# Polarfire SoC register map
Vendor: Microchip; File version: 1.0
CPU: Microchip PolarFire SoC 1.0, little endian
Registers are 32-bit, read-write, reset 0x0 unless marked. A register's access mark holds for its fields unless they carry their own. Offsets are from the block's base; [hi:lo] are bit positions; lines under a group give offsets from that group; {n}, {i} and the like mark numbered series.

## EMMC_SD (part 2 of 2) — EMMC_SD Controller
Base 0x20008000
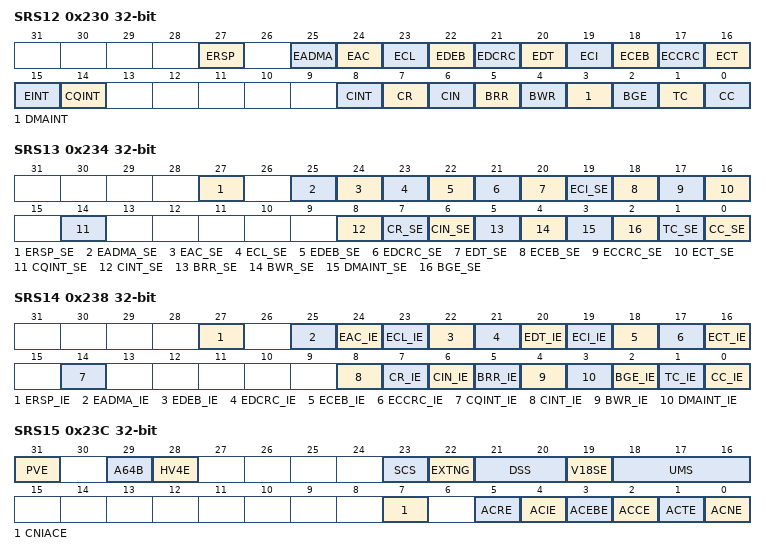
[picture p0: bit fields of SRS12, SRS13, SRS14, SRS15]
0x230 SRS12 — SRS12 - Error/Normal Interrupt Status
  [27] ERSP — ERSP - Response Error (SD Mode only) Generated on error detection inside R1 or R5 response. Errors will be checked only if RECE is set 1.
  [25] EADMA — EADMA - ADMA Error Generated when an error occurs during ADMA read or write transfer. To resolve the cause of the error, the state of the ADMA engine at error occurrence is saved in ADMA Error Status register, and the address of the descriptor processed at error occurrence is provided in ADMA System Address register.
  [24] EAC — EAC - Auto CMD Error (SD mode only) Generated when an error occurs during Auto CMD12/Auto CMD23 command transmission. It indicates one of the following conditions: - one of the bits in SRS15 register has changed from 0 to 1, - Auto CMD12 is not executed due to the previous command error.
  [23] ECL — ECL - Current Limit Error Generated when host is not supplying power to SD card due to some failure. The value is equal to the actual signal level on cle pin of the host.
  [22] EDEB — EDEB - Data End Bit Error (SD mode only) When set to 1, indicates detecting 0 at the end bit position of read data transfer which uses the DAT line, or at the end bit position of the Write CRC Status.
  [21] EDCRC — EDCRC - Data CRC Error (SD mode only) When set to 1, indicates detecting CRC error when transferring read data which uses the DAT line, or when detecting the Write CRC status having a value of other than 010. This bit will be set to 1 immediately when conflict on CMD line detected. The conflict is signalized by setting this bit and SRS12.EDT to 1.
  [20] EDT — EDT - Data Timeout Error (SD mode only) When set to 1, indicates detecting one of the following timeout conditions: 1. Busy timeout for the response with busy. 2. Busy timeout after Write CRC status. 3. Write CRC Status timeout. 4. Read data timeout. This bit will be set to 1 immediately when conflict on CMD line conflict detected.
  [19] ECI — ECI - Command Index Error (SD mode only) When set to 1, indicates that Index error occurs in the command response.
  [18] ECEB — ECEB - Command End Bit Error (SD mode only) When set to 1, indicates detecting that the end bit of a command response is 0.
  [17] ECCRC — ECCRC - Command CRC Error (SD mode only) When set to 1, indicates that command CRC error has occurred.
  [16] ECT — ECT - Command Timeout Error (SD mode only) When set to 1, indicates that no response was returned within 64 SDCLK cycles from the end bit of the command.
  [15] EINT ro — EINT - Error Interrupt This bit is set if: - any of bits in range SRS12[31:16] is set; The software can check for an error by reading this single bit first.
  [14] CQINT ro — CQINT - Command Queuing Interrupt This interrupt is asserted when at least one of the bits in CQIS register is set. This interrupt is cleared only by clearing the source interrupt in CQIS register.
  [8] CINT ro — CINT - Card Interrupt Indicates the card interrupt. CINT is not sampled by the card clock, so the interrupt can be detected even with SD clock stopped (SRS11.SDCE=0). Also, CINT is not cleared by writing 1. Instead, the software will clear the source of an interrupt inside the card.After detecting the Card Interrupt, the software will stop further interrupt detection by clearing SRS13.CINT_SE to 0. Then, the software will clear the interrupt source inside the card by using the appropriate commands. For the details, please refer to the SDIO Card Specification. After clearing the interrupt source, the card will stop to drive the interrupt signal to the host. Finally, when the interrupt service routine is finished, the interrupt detection can be enabled by setting SRS13.CINT_SE back to 1.
  [7] CR — CR - Card Removal Generated when the SRS09.CI bit changes from 1 to 0, indicating card removal event. When read as 1, indicates that the card was removed from the slot. When read as 0, indicates that the card state is stable (still inserted or removed) or that the debouncing is in progress.
  [6] CIN — CIN - Card Insertion Generated when the SRS09.CI bit changes from 0 to 1, indicating card insertion. When read as 1, indicates that the card was inserted to the slot. When read as 0, indicates that the card state is stable (still inserted or removed) or that the debouncing is in progress.
  [5] BRR — BRR - Buffer Read Ready Generated when the BRE changes from 0 to 1, indicating that the data buffer can be read by the software.
  [4] BWR — BWR - Buffer Write Ready Generated when the BWE changes from 0 to 1, indicating that the data buffer can be written by the software.
  [3] DMAINT — DMAINT - DMA Interrupt In SDMA mode, DMA interrupt is generated when the host controller detects the Host SDMA Buffer boundary. In ADMA mode, DMA interrupt is generated when the INT flag is set in a currently serviced ADMA descriptor.
  [2] BGE — BGE - Block Gap Event Generated when the read/write transaction is stopped at a block gap as the result of setting SRS10.SBGR to 1.
  [1] TC — TC - Transfer Complete SD Mode: Generated when the transfer which uses the DAT line is complete. Transfers which use the DAT line include the read/write transfers and commands with a busy response. In case of the read transfer, TC indicates that the entire data was transferred from the card to the host system (i.e. the host FIFO is empty after reading the last data block). In case of the write transfer, TC indicates that the entire data was transferred from the host to the card (i.e. the host FIFO is empty after writing the last data block), and the card accepted the data (busy signal released after the last block). In the case of the command with a busy response, TC indicates that the busy signal is released after the response.
  [0] CC — CC - Command Complete Generated when the end bit of the response is received, except the response for Auto-CMD12 command. Auto-CMD12 command does not generate CC.
0x234 SRS13 — SRS13 - Error/Normal Status Enable
  [27] ERSP_SE — ERSP_SE - Response Error Status Enable (SD mode only) 1 - enabled 0 - masked
  [25] EADMA_SE — EADMA_SE - ADMA Error Status Enable (SD mode only) 1 - enabled 0 - masked
  [24] EAC_SE — EAC_SE - Auto CMD Error Status Enable (SD mode only) 1 - enabled 0 - masked
  [23] ECL_SE — ECL_SE - Current Limit Error Status Enable (SD mode only) 1 - enabled 0 - masked
  [22] EDEB_SE — EDEB_SE - Data End Bit Error Status Enable (SD mode only) 1 - enabled 0 - masked
  [21] EDCRC_SE — EDCRC_SE - Data CRC Error Status Enable (SD mode only) 1 - enabled 0 - masked
  [20] EDT_SE — EDT_SE - Data Timeout Error Status Enable (SD mode only) 1 - enabled 0 - masked
  [19] ECI_SE — ECI_SE - Command Index Error Status Enable (SD mode only) 1 - enabled 0 - masked
  [18] ECEB_SE — ECEB_SE - Command End Bit Error Status Enable (SD mode only) 1 - enabled 0 - masked
  [17] ECCRC_SE — ECCRC_SE - Command CRC Error Status Enable (SD mode only) 1 - enabled 0 - masked
  [16] ECT_SE — ECT_SE - Command Timeout Error Status Enable (SD mode only) 1 - enabled 0 - masked
  [14] CQINT_SE — CQINT_SE - Command Queuing Status Enable 1 - enabled 0 - masked
  [8] CINT_SE — CINT_SE - Card Interrupt Status Enable 1 - enabled 0 - masked
  [7] CR_SE — CR_SE - Card Removal Status Enable 1 - enabled 0 - masked
  [6] CIN_SE — CIN_SE -Card Insertion Status Enable 1 - enabled 0 - masked
  [5] BRR_SE — BRR_SE - Buffer Read Ready Status Enable 1 - enabled 0 - masked
  [4] BWR_SE — BWR_SE - Buffer Write Ready Status Enable 1 - enabled 0 - masked
  [3] DMAINT_SE — DMAINT_SE - DMA Interrupt Status Enable 1 - enabled 0 - masked
  [2] BGE_SE — BGE_SE - Block Gap Event Status Enable 1 - enabled 0 - masked
  [1] TC_SE — TC_SE - Transfer Complete Status Enable 1 - enabled 0 - masked
  [0] CC_SE — CC_SE - Command Complete Status Enable 1 - enabled 0 - masked
0x238 SRS14 — SRS14 - Error/Normal Signal Enable
  [27] ERSP_IE — ERSP_IE - Response Error Interrupt Enable 1 - enabled 0 - masked
  [25] EADMA_IE — EADMA_IE - ADMA Error Interrupt Enable (SD mode only) 1 - enabled 0 - masked
  [24] EAC_IE — EAC_IE - Auto CMD Error Interrupt Enable (SD mode only) 1 - enabled 0 - masked
  [23] ECL_IE — ECL_IE - Current Limit Error Interrupt Enable (SD mode only) 1 - enabled 0 - masked
  [22] EDEB_IE — EDEB_IE - Data End Bit Error Interrupt Enable (SD mode only) 1 - enabled 0 - masked
  [21] EDCRC_IE — EDCRC_IE - Data CRC Error Interrupt Enable (SD mode only) 1 - enabled 0 - masked
  [20] EDT_IE — EDT_IE - ata Timeout Error Interrupt Enable (SD mode only) 1 - enabled 0 - masked
  [19] ECI_IE — ECI_IE - Command Index Error Interrupt Enable (SD mode only) 1 - enabled 0 - masked
  [18] ECEB_IE — ECEB_IE - Command End Bit Error Interrupt Enable (SD mode only) 1 - enabled 0 - masked
  [17] ECCRC_IE — ECCRC_IE - Command CRC Error Interrupt Enable (SD mode only) 1 - enabled 0 - masked
  [16] ECT_IE — ECT_IE - Command Timeout Error Interrupt Enable (SD mode only) 1 - enabled 0 - masked
  [14] CQINT_IE — CQINT_IE - Command Queuing - Interrupt Enable 1 - enabled 0 - masked
  [8] CINT_IE — CINT_IE - Card Interrupt - Interrupt Enable 1 - enabled 0 - masked
  [7] CR_IE — CR_IE - Card Removal Interrupt Enable 1 - enabled 0 - masked
  [6] CIN_IE — CIN_IE - Card Insertion Interrupt Enable 1 - enabled 0 - masked
  [5] BRR_IE — BRR_IE - Buffer Read Ready Interrupt Enable 1 - enabled 0 - masked
  [4] BWR_IE — BWR_IE - Buffer Write Ready Interrupt Enable 1 - enabled 0 - masked
  [3] DMAINT_IE — DMAINT_IE - DMA Interrupt Enable 1 - enabled 0 - masked
  [2] BGE_IE — BGE_IE - Block Gap Event Interrupt Enable 1 - enabled 0 - masked
  [1] TC_IE — TC_IE - Transfer Complete Interrupt Enable 1 - enabled 0 - masked
  [0] CC_IE — CC_IE - Command Complete Interrupt Enable 1 - enabled 0 - masked
0x23C SRS15 — SRS15 - Host Control #2 / Auto CMD Error Status
  [31] PVE — PVE - Preset Value Enable Setting this bit to 1 triggers an automatically update of SRS11.SDCFSL, SRS11.SDCFSH, SRS11.CGS, SRS15.DSS registers by the host. Values for an update are taken from SRS24 - SRS27 and depends on SRS15.UMS.
  [29] A64B — A64B - 64-bit Addressing Specifies the addressing mode for DMA ending. This field is ignored when SRS15.HV4E=0. 0 - 32-bit addressing 1 - 64-bit addressing
  [28] HV4E — HV4E - Host Version 4.00 Enable Selects backward (SD Host 3.00 Version) compatibility mode or SD Host 4.00 Version mode. 0 - Version 3.00 1 - Version 4.00 The software can select system address register SRS00 (when this bit is 0) or SRS23 / SRS22 (when this bit is 1) for the SDMA engine.
  [23] SCS — SCS - Sampling Clock Select (UHS-I only) The host updates this bit when the tuning procedure is finished. If this bit is set to 1, this means that the tuning procedure is successfully completed. Otherwise it means that procedure failed and clock tuning logic is disabled. This bit is valid only after the procedure is finished.Writing 1 will be ignored. Writing 0 will reset and disable tuning block.
  [22] EXTNG — EXTNG - Execute Tuning (UHS-I only) This register controls tuning procedure. The procedure starts when the bit is set 1. The procedure can be aborted when the bit is cleared. The bit is read 1 while the procedure is in progress, and 0 when the procedure is finished. SCS = 0, EXTNG = 0 - Reset and disable clock tuning logic SCS = 0, EXTNG = 1 - Reset and restart tuning process SCS = 1, EXTNG = 0 - Stop tuning procedure SCS = 1, EXTNG = 1 - Start retuning (without clock tuning logic reset)
  [21:20] DSS — DSS - Driver Strength Select (UHS-I only) This bit controls the electric parameters of I/O driver. Up to 4 configurations of I/O driver settings can be implemented: 00 - Driver Type B (default) 01 - Driver Type A 10 - Driver Type C 11 - Driver Type D The bit is ignored when the V18SE is cleared.
  [19] V18SE — V18SE - 1.8V Signaling Enable (UHS-I only) This bit controls I/O signaling voltage level. If the bit is 0 or 1, the I/O uses the 3.3V or 1.8V signaling, respectively. The SW driver will set this bit 1 when UHS-I mode. Depend on the selected SD interface mode, the software will set this field as follows: - 0 - for Default Speed, High Speed mode - 1 - for UHS-I mode
  [18:16] UMS — UMS - UHS Mode Select Used to select one of UHS-I modes . 000b - SDR12 001b - SDR25 010b - SDR50 011b - SDR104 100b - DDR50 101b - Reserved 110b - Reserved 111b - Reserved The selected UHS-I mode (when value is in range 000b-100b) will be ignored when V18SE is 0.
    0=SDR12; 1=SDR25; 2=SDR50; 3=SDR104; 4=DDR50; 6=Reserverd2
  [7] CNIACE ro — CNIACE - Command Not Issued By Auto CMD12 Error When read as 1, the command was not executed by the Host due to the previous Auto CMD12 error. When Host detects any error during Auto-CMD12, then all further command generation attempts are blocked. The software reset sequence is needed for recovery. Bit is set to 0, when Auto CMD23 Error is detected (any of bits SRS15[4:1] is set).
  [5] ACRE ro — ACRE - Auto CMD Response Error When read as 1, means an error is detected in response to Auto Command.
  [4] ACIE ro — ACIE - Auto CMD Index Error When read as 1, means that Command Index error occurred in the Auto CMD response.
  [3] ACEBE ro — ACEBE - Auto CMD End Bit Error When read as 1, indicates that the end bit of the Auto-CMD response is 0.
  [2] ACCE ro — ACCE - Auto CMD CRC Error When read as 1, indicates a CRC error was detected in the Auto CMD response or conflict on the CMD lines is detected: ACCE(SRS15.2) = 0, ACTE(SRS15.1) = 0 - No error ACCE(SRS15.2) = 0, ACTE(SRS15.1) = 1 - Auto CMD Timeout error detected ACCE(SRS15.2) = 1, ACTE(SRS15.1) = 0 - Auto CMD CRC error detected ACCE(SRS15.2) = 1, ACTE(SRS15.1) = 1 - Conflict on the CMD line detected
  [1] ACTE ro — ACTE - Auto CMD Timeout Error When read as 1, indicates that there was no response within 64 SDCLK clock cycles from the end bit of the Auto CMD or conflict on the CMD lines is detected (see table in SRS15.ACCE field description). If this bit is set to 1, the other error status bits (SRS15[4:2]) are meaningless.
  [0] ACNE ro — ACNE - Auto CMD12 Not Executed When set to 1, means the host cannot issue Auto CMD12 due to some error. If this bit is set to 1, other error status bits (SRS15[4:1]) are meaningless. Bit is updated with 0, when Auto CMD23 Error is detected (any of bits SRS15[4:1] is set).
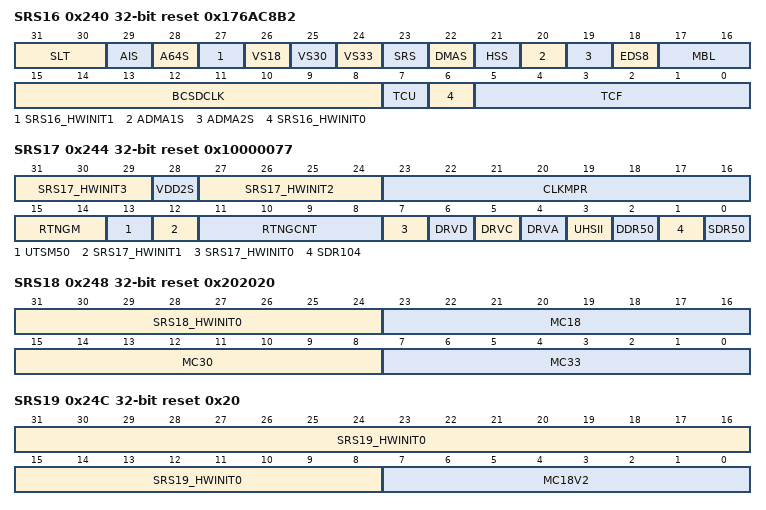
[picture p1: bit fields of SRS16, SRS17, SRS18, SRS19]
0x240 SRS16 ro reset 0x176AC8B2 — SRS16 - Capabilities #1 HWINIT Register - Note this register is hardware initialized after reset and the value read back will match the IP configuration.
  [31:30] SLT — SLT - Slot Type These bits inform what type of slot is provided. 00 - Removable Card Slot 01 - Embedded Slot for One Device 10 - Shared Bus Slot 11 - Reserved
  [29] AIS — AIS - Asynchronous Interrupt Support 0 - not supported 1 - supported
  [28] A64S — A64S - 64-bit System Addressing Support 0 - not supported 1 - supported
  [27] SRS16_HWINIT1 — HWINIT field
  [26] VS18 — VS18 - Voltage Support 1.8V 0 - not supported 1 - supported
  [25] VS30 — VS30 - Voltage Support 3.0V 0 - not supported 1 - supported
  [24] VS33 — VS33 - Voltage Support 3.3V 0 - not supported 1 - supported
  [23] SRS — SRS - Suspend / Resume Support 0 - not supported 1 - supported The host controller does not support Suspend / Resume mechanism.
  [22] DMAS — DMAS - SDMA Support 0 - not supported 1 - supported This bit defines whether the SDMA is supported in the slot. There is a separate IMPLEMENT_DMA generic parameter which defines whether the DMA is physically implemented inside host. If DMAS is set to 1 for any card slot, then the IMPLEMENT_DMA would also be set to 1.
  [21] HSS — HSS - High Speed Support 0 - not supported 1 - supported
  [20] ADMA1S — ADMA1S - ADMA1 Support 0 - not supported 1 - supported
  [19] ADMA2S — ADMA2S - ADMA2 Support 0 - not supported 1 - supported
  [18] EDS8 — 8EDS - 8-bit Embedded Device Support 0 - not supported 1 - supported If this bit is 0, the SRS10.EDTW register is not implemented.
  [17:16] MBL — SRS16.MBL - Max Block Length This value indicates the maximum block size that can be transferred by the host. Three sizes can be defined as indicated below: 00b - 512 Bytes 01b - 1024 Bytes 10b - 2048 Bytes 11b - Reserved The physical FIFO buffer size is defined by the separate FIFODEPTH generic parameter, and the physical buffer size is equal to 2^FIFODEPTH * 8 bytes. Therefore, the Maximum Block Size defined by MBL will always be less or equal to the physical buffer size.
  [15:8] BCSDCLK — BCSDCLK - Base Clock Frequency for SD Clock Field defines the base clock frequency for the SD Clock in 1MHz units. The base clock is the clock sourced to sdmclk pin of the host. The maximum clock frequency supported is between 10MHz to 255MHz. If BCSDCLK = 0, the Host System has to obtain the clock information via another method (i.e. not defined by the specification).
  [7] TCU — TCU - Timeout Clock Unit Field defines the frequency unit for the SRS16.TCF. 0 - kHz 1 - MHz
  [6] SRS16_HWINIT0 — HWINIT field
  [5:0] TCF — TCF - Timeout Clock Frequency Defines the base clock frequency used to detect Data Timeout Error. The SRS16.TCU bit determines the unit used. 111111b - 63kHz(SRS16.TCU=0) or 63MHz(SRS16.TCU=1) 111110b - 63kHz(SRS16.TCU=0) or 63MHz(SRS16.TCU=1) ... 000001b - 1kHz(SRS16.TCU=0) or 1MHz(SRS16.TCU=1) 000000b - Host System has to obtain the clock information via another method (i.e. not defined by the spec).
0x244 SRS17 ro reset 0x10000077 — SRS17 - Capabilities #2HWINIT Register - Note this register is hardware initialized after reset and the value read back will match the IP configuration.
  [31:29] SRS17_HWINIT3 — HWINIT field
  [28] VDD2S — VDD2S - VDD2 Supported Information about support or lack of support of optional VDD2.
  [27:24] SRS17_HWINIT2 — HWINIT field
  [23:16] CLKMPR — CLKMPR - Clock Multiplier This field is to be 0 (fixed), as the Clock Multiplier is not supported.
  [15:14] RTNGM — RTNGM - Re-Tuning Modes Depending on the retuning method, the some restrictions are assumed for the data length between re-tunings. The core can work with supporting one of the three method: 0 - Mode1: The software driver will use timer to calculate when the re-tuning is to be rerun. The data length between operations is limited to the 4MB. 1 - Mode2: The driver will use either the re-tuning request (external input pin uhsi_retune_req is used for this purpose) or timer to predict when next retuning should be performed. The data length between operations is limited to the 4MB. 2 - Mode3: This mode is similar to the mode2 with one exception. The core is able to perform auto retuning during the transmission, so data length limitation is not exists. Mode 3 is currently not supported.The driver can configure the timer by getting the RTNGCNT.This field is to be 0 or 1, because the mode 3 is not supported.
  [13] UTSM50 — UTSM50 - Use Tuning for SDR50 1 - tuning operation is necessary in SDR50 mode 0 - tuning operation is not necessary in SDR50 mode
  [12] SRS17_HWINIT1 — HWINIT field
  [11:8] RTNGCNT — RTNGCNT - Timer Count for Re-Tuning These bits contain initial value for timer used to starting periodically Re-Tuning Operation. 0h - Re-Tuning Timer disabled 1h - 1 second ... n - 2^(n-1) seconds ... Bh - 1024 seconds Eh-Ch - Reserved Fh - Obtain this info in other way
  [7] SRS17_HWINIT0 — HWINIT field
  [6] DRVD — DRVD - 1.8V Line Driver Type D Supported 1 - Driver Type D supported 0 - Driver Type D not supported
  [5] DRVC — DRVC - 1.8V Line Driver Type C Supported 1 - Driver Type C supported 0 - Driver Type C not supported
  [4] DRVA — DRVA - 1.8V Line Driver Type A Supported 1 - Driver Type A supported 0 - Driver Type A not supported
  [3] UHSII — UHSII - UHS-II Supported 1 - UHS-II supported 0 - UHS-II not supported
  [2] DDR50 — DDR50 - DDR50 Supported 1 - DDR50 mode supported 0 - DDR50 mode not supported
  [1] SDR104 — SDR104 - SDR104 Supported 1 - SDR104 mode supported 0 - SDR104 mode not supported
  [0] SDR50 — SDR50 - SDR50 Supported 1 - SDR50 mode supported 0 - SDR50 mode not supported
0x248 SRS18 ro reset 0x202020 — SRS18 - Capabilities #3HWINIT Register - Note this register is hardware initialized after reset and the value read back will match the IP configuration.
  [31:24] SRS18_HWINIT0 — HWINIT field
  [23:16] MC18 — MC18 - Maximum Current for 1.8V 0 - Host System has to obtain the current value via another method 1 - 4 mA 2 - 8 mA 3 - 12 mA ... 255 - 1020 mA
  [15:8] MC30 — MC30 - Maximum Current for 3.0V 0 - Host System has to obtain the current value via another method 1 - 4 mA 2 - 8 mA 3 - 12 mA ... 255 - 1020 mA
  [7:0] MC33 — MC33 - Maximum Current for 3.3V 0 - Host System has to obtain the current value via another method 1 - 4 mA 2 - 8 mA 3 - 12 mA ... 255 - 1020 mA
0x24C SRS19 ro reset 0x20 — SRS19 - Capabilities #4 HWINIT Register - Note this register is hardware initialized after reset and the value read back will match the IP configuration.
  [31:8] SRS19_HWINIT0 — HWINIT field
  [7:0] MC18V2 — MC18V2 - Maximum Current for 1.8V VDD2 0 - Host System has to obtain the current value via another method 1 - 4 mA 2 - 8 mA 3 - 12 mA ... 255 - 1020 mA
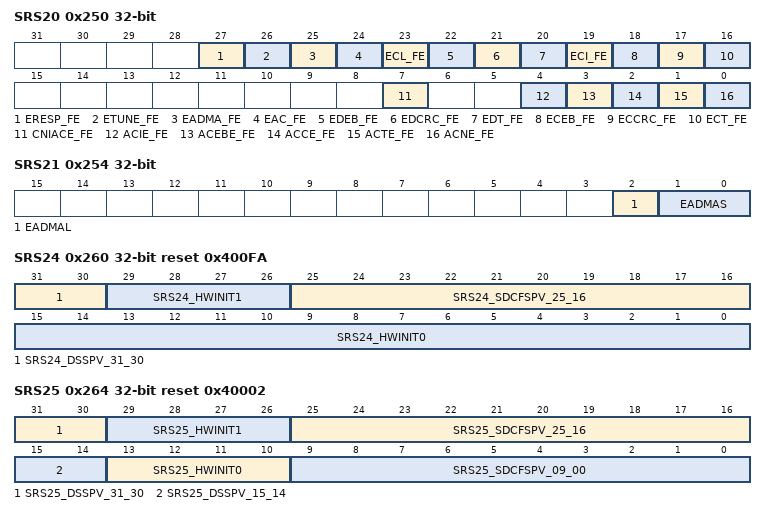
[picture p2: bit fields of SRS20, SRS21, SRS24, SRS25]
0x250 SRS20 — SRS20 - Force Event Each field of this register is related to the specific error status. Writing 1 to field will set the status error. This function is provided for SW debug purpose.
  [27] ERESP_FE — ERESP_FE - Force Response Error Event
  [26] ETUNE_FE — ETUNE_FE - Force Tuning Error Event
  [25] EADMA_FE — EADMA_FE - Force ADMA Error Event
  [24] EAC_FE — EAC_FE - Force Auto CMD Error Event
  [23] ECL_FE — ECL_FE - Force Current Limit Error Event
  [22] EDEB_FE — EDEB_FE - Force Data End Bit Error Event
  [21] EDCRC_FE — EDCRC_FE - Force Data CRC Error Event
  [20] EDT_FE — EDT_FE - Force Data Timeout Error Event
  [19] ECI_FE — ECI_FE - Force Command Index Error Event
  [18] ECEB_FE — ECEB_FE - Force Command End Bit Error Event
  [17] ECCRC_FE — ECCRC_FE - Force Command CRC Error Event
  [16] ECT_FE — ECT_FE - Force Command Timeout Error Event
  [7] CNIACE_FE — CNIACE_FE - Force Command Not Issued By Auto CMD12 Error Event
  [4] ACIE_FE — ACIE_FE - Force Auto CMD Index Error Event
  [3] ACEBE_FE — ACEBE_FE - Force Auto CMD End Bit Error Event
  [2] ACCE_FE — ACCE_FE - Force Auto CMD CRC Error Event
  [1] ACTE_FE — ACTE_FE - Force Auto CMD Timeout Error Event
  [0] ACNE_FE — ACNE_FE - Force Auto CMD12 Not Executed Event
0x254 SRS21 ro — SRS21 - ADMA Error Status
  [2] EADMAL — EADMAL - ADMA Length Mismatch Error This bit is set when: - total data length specified in ADMA descriptors is different from that specified by the Block Count and Block Length fields (if Block Count Enable is set). - total data length cannot be divided into complete blocks of specified length (if Block Count Enable is not set).
  [1:0] EADMAS — EADMAS - ADMA Error State The value of this field reflects the state of the ADMA state machine. The possible values are: 00b - ST_STOP (ADMA Stopped) 01b - ST_FDS (Fetching descriptor) 10b - not used 11b - ST_TRF (Transfer data)
0x258 SRS22 — SRS22 ADMA/SDMA System Address 1
  [31:0] DMASA1 — DMASA1 - ADMA System Address This field contains the physical address of the currently processed ADMA descriptor or SDMA system address. The Host Driver will set this register with the descriptors table base address before it starts the ADMA transfers. The Host Driver should not write this register while the data transfer is active. While the ADMA engine is processing the descriptors list, the ADMASA value is always incremented to point the next descriptor to be fetched. If the ADMA Error occurs, the register holds the descriptor address depending on the ADMA Error State (SRS21.EADMAS) register value, as listed in the table below: 00b - Points next of the error descriptor 01b - Points the error descriptor 10b - not used 11b - Points next of the error descriptor The host ADMA engine ignores 2 or 3 least significant bits in this register when the 32-bit or 64-bit addressing is active, respectively. If SRS15.HV4E is set 1 and SDMA engine is selected, this field is used instead of SRS00 to define system memory address. This register incremented and points to the next memory location that will be accessed.
0x25C SRS23 — SRS23 ADMA/SDMA System Address 2
  [31:0] DMASA2 — DMASA2 - ADMA System Address #2 In ADMA mode, if 64-bit addressing is enabled (SRS15.A64B=1), this field holds bits 63-32 of the physical address pointing on ADMA descriptor table. In SDMA mode, if host compatibility with version 4.x and 64-bit addressing are enabled (SRS15.HV4E=1 and SRS15.A64B=1), this field holds bits 63-32 of system address.
0x260 SRS24 ro reset 0x400FA — SRS24 - Preset Value (Default Speed) SRS24[31:16] - Default Speed if: SRS15.V18SE=0 SRS10.HSE=0 HWINIT Register - Note this register is hardware initialized after reset and the value read back will match the IP configuration.
  [31:30] SRS24_DSSPV_31_30 — DSSPV## - Driver Strength Select - Preset Value This field can be used by the software to update SRS15.DSS.
  [29:26] SRS24_HWINIT1 — HWINIT field
  [25:16] SRS24_SDCFSPV_25_16 — SDCFSPV## - SDCLK Clock Frequency Select - Preset Value This field can be used by the software to update SRS11.SDCFSH and SRS11.SDCFSL.
  [15:0] SRS24_HWINIT0 — HWINIT field
0x264 SRS25 ro reset 0x40002 — SRS25 - Preset Value (High Speed and SDR12) SRS25[15:0] - High Speed if: SRS15.V18SE=0 SRS.HSE=1 SRS25[31:16] - SDR12 if: SRS15.V18SE=1 SRS15.UMS=000b HWINIT Register - Note this register is hardware initialized after reset and the value read back will match the IP configuration.
  [31:30] SRS25_DSSPV_31_30 — DSSPV## - Driver Strength Select - Preset Value This field can be used by the software to update SRS15.DSS.
  [29:26] SRS25_HWINIT1 — HWINIT field
  [25:16] SRS25_SDCFSPV_25_16 — SDCFSPV## - SDCLK Clock Frequency Select - Preset Value This field can be used by the software to update SRS11.SDCFSH and SRS11.SDCFSL.
  [15:14] SRS25_DSSPV_15_14 — DSSPV## - Driver Strength Select - Preset Value This field can be used by the software to update SRS15.DSS.
  [13:10] SRS25_HWINIT0 — HWINIT field
  [9:0] SRS25_SDCFSPV_09_00 — SDCFSPV## - SDCLK Clock Frequency Select - Preset Value This field can be used by the software to update SRS11.SDCFSH and SRS11.SDCFSL.
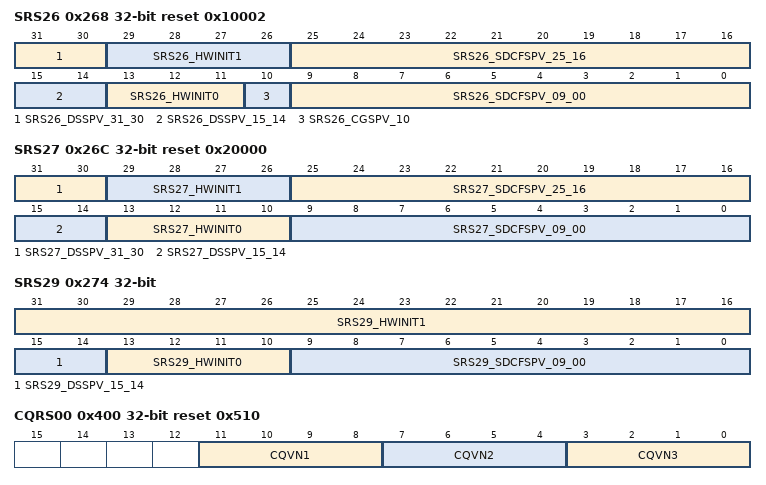
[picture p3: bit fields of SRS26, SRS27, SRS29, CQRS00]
0x268 SRS26 ro reset 0x10002 — SRS26 - Preset Value (SDR25 and SDR50) SRS26[15:0] - SDR25 if: SRS15.V18SE=1 SRS15.UMS=001b SRS26[31:16] - SDR50 if: SRS15.V18SE=1 SRS15.UMS=010b HWINIT Register - Note this register is hardware initialized after reset and the value read back will match the IP configuration.
  [31:30] SRS26_DSSPV_31_30 — DSSPV## - Driver Strength Select - Preset Value This field can be used by the software to update SRS15.DSS.
  [29:26] SRS26_HWINIT1 — HWINIT field
  [25:16] SRS26_SDCFSPV_25_16 — SDCFSPV## - SDCLK Clock Frequency Select - Preset Value This field can be used by the software to update SRS11.SDCFSH and SRS11.SDCFSL.
  [15:14] SRS26_DSSPV_15_14 — DSSPV## - Driver Strength Select - Preset Value This field can be used by the software to update SRS15.DSS.
  [13:11] SRS26_HWINIT0 — HWINIT field
  [10] SRS26_CGSPV_10 — CGSPV## - Clock Generator Select - Preset Value This field can be used by the software to update SRS11.CGS.
  [9:0] SRS26_SDCFSPV_09_00 — SDCFSPV## - SDCLK Clock Frequency Select - Preset Value This field can be used by the software to update SRS11.SDCFSH and SRS11.SDCFSL.
0x26C SRS27 ro reset 0x20000 — SRS27 - Preset Value (SDR104 and DDR50) SRS27[15:0] - SDR104 if: SRS15.V18SE=1 SRS15.UMS=011b SRS27[31:16] - DDR50 if: SRS15.V18SE=1 SRS15.UMS=100b HWINIT Register - Note this register is hardware initialized after reset and the value read back will match the IP configuration.
  [31:30] SRS27_DSSPV_31_30 — DSSPV## - Driver Strength Select - Preset Value This field can be used by the software to update SRS15.DSS.
  [29:26] SRS27_HWINIT1 — HWINIT field
  [25:16] SRS27_SDCFSPV_25_16 — SDCFSPV## - SDCLK Clock Frequency Select - Preset Value This field can be used by the software to update SRS11.SDCFSH and SRS11.SDCFSL.
  [15:14] SRS27_DSSPV_15_14 — DSSPV## - Driver Strength Select - Preset Value This field can be used by the software to update SRS15.DSS.
  [13:10] SRS27_HWINIT0 — HWINIT field
  [9:0] SRS27_SDCFSPV_09_00 — SDCFSPV## - SDCLK Clock Frequency Select - Preset Value This field can be used by the software to update SRS11.SDCFSH and SRS11.SDCFSL.
0x274 SRS29 ro — SRS29 - Preset Value for UHS-II SRS29[15:0] - UHS-II if: SRS15.V18SE=0 SRS15.UMS=111b HWINIT Register - Note this register is hardware initialized after reset and the value read back will match the IP configuration.
  [31:16] SRS29_HWINIT1 — HWINIT field
  [15:14] SRS29_DSSPV_15_14 — DSSPV## - Driver Strength Select - Preset Value This field can be used by the software to update SRS15.DSS.
  [13:10] SRS29_HWINIT0 — HWINIT field
  [9:0] SRS29_SDCFSPV_09_00 — SDCFSPV## - SDCLK Clock Frequency Select - Preset Value This field can be used by the software to update SRS11.SDCFSH and SRS11.SDCFSL.
0x400 CQRS00 ro reset 0x510 — CQRS00 - Command Queuing Version
  [11:8] CQVN1 — CQVN1 - eMMC Major Version Number Major version number of supported eMMC standard - 5.
  [7:4] CQVN2 — CQVN2 - eMMC Minor Version Number Minor version number of supported eMMC standard - 1.
  [3:0] CQVN3 — CQVN3 - eMMC Version Suffix Suffix version number of supported eMMC standard - 0.
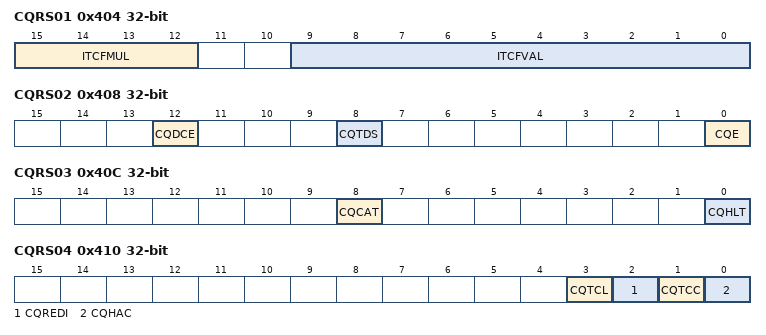
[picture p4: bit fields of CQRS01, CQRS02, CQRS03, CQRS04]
0x404 CQRS01 ro — CQRS01 - Command Queuing Capabilities
  [15:12] ITCFMUL — ITCFMUL - Internal Timer Clock Frequency Multiplier (ITCFMUL) Defines multiplier of internal clock frequency for the coalescing timer and for the SQS polling period. 0 - 0.001 MHz 1 - 0.01 MHz 2 - 0.1 MHz 3 - 1 MHz 4 - 10 MHz The ITCFMUL and ITCFVAL defines the clock frequency.
  [9:0] ITCFVAL — ITCFVAL - Internal Timer Clock Frequency Value (ITCFVAL) Value defines internal clock frequency for the coalescing timer and for the SQS polling period. The frequency is equal to ITCFMUL * ITCFVAL.
0x408 CQRS02 — CQRS02 - Command Queuing Configuration
  [12] CQDCE — CQDCE - Direct Command (DCMD) Enable Process Task Descriptor for slot 31 as Data Transfer Task Descriptor (0) or Direct Command Task Descriptor (1).
  [8] CQTDS — CQTDS - Task Descriptor Size Expect 128 bit (1) or 64 bit (0) task descriptor. This setting can be changed only when Command Queuing is disabled (CQE = 0).
  [0] CQE — CQE - Command Queuing Enable Enables (1) or disables (0) the Command Queuing. This bit can be enabled only when all previous transactions are completed. This bit can be cleared only when all tasks are completed or cleared.
0x40C CQRS03 — CQRS03 - Command Queuing Control
  [8] CQCAT — CQCAT - Clear All Tasks Clears (1) all active tasks in the host controller. Software has to poll this register until operation is completed (bit is automatically cleared). Software can set this bit only when the CQ Engine is halted. Software has to clear all requested tasks in the eMMC device. Writing (0) has no effect.
  [0] CQHLT — CQHLT - Halt CQ Engine can be halted by writing this bit 1. Any pending operation will be completed, and awaiting operation will be stopped. Once all tasks are completed or stopped this bit is set 1. The host controller will not automatically start any new operation, but software can use SRS registers to issue any command directly bypassing CQE. CQ Engine starts operation after being halted by writing 0 to this register. Writing 0 is ignored when CQ Engine is not halted.
0x410 CQRS04 — CQRS04 - Command Queuing Interrupt Status This register has several status bit related to specific interrupt event. When even happened and related Command Queuing Interrupt Status Enable is set, the status bit is set to 1. The bits can be cleared by S/W. Write 0 clears bit. Write 1 is ignored.
  [3] CQTCL — CQTCL - Task Cleared (TCL) When task clear operation or clear individual task is completed, the CQE sets this bit to 1.
  [2] CQREDI — CQREDI - Response Error Detected Interrupt (RED) When an error is detected in the response received from eMMC device, the CQE sets this bit to 1. S/W can select which bits are analyzed by selecting CQRMEM.
  [1] CQTCC — CQTCC - Task Complete Interrupt (TCC) CQE sets this bit when either a task with INT=1 is completed or Interrupt Coalescing reports interrupt.
  [0] CQHAC — CQHAC - Halt Complete Interrupt (HAC) CQE sets this bit when value of CQHLT changed from 0 to 1.
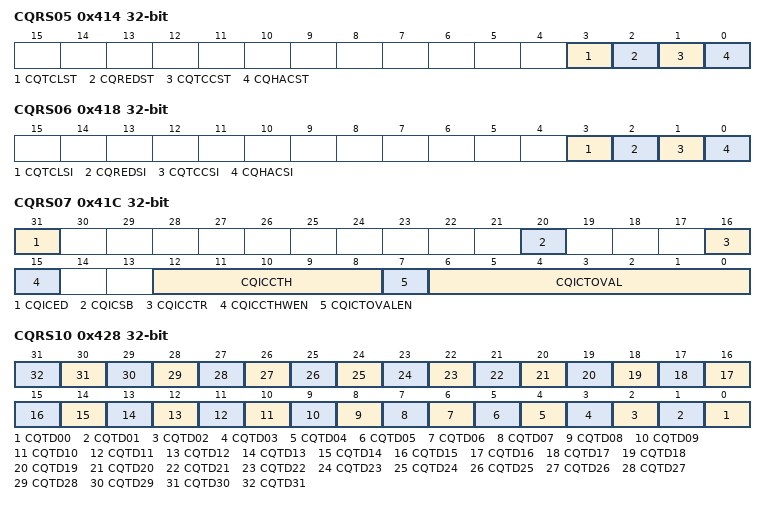
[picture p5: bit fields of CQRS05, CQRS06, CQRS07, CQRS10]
0x414 CQRS05 — CQRS05 - Command Queuing Interrupt Status Enable Statuses Enable bits enables interrupt sources. The status is enabled when bit is set 1 (S/W wrote 1 to the field).
  [3] CQTCLST — CQTCLST - Task Cleared Status Enable (TCL) Enables CQTCL register.
  [2] CQREDST — CQREDST - Response Error Detected Status Enable (RED) Enables CQREDI register.
  [1] CQTCCST — CQTCCST - Task Complete Status Enable (TCC) Enables CQHAC register.
  [0] CQHACST — CQHACST - Halt Complete Status Enable (HAC) Enables CQTCLST register.
0x418 CQRS06 — CQRS06 - Command Queuing Interrupt Signal Enable This register allows to turn on or turn off interrupt notification separately for each bit of the Command Queuing Interrupt Status. When Interrupt status bit is set 1 and related field in this register is set (S/W wrote 1 to the filed), the Interrupt Status is reported on interrupt port.
  [3] CQTCLSI — CQTCLSI - Task Cleared Signal Enable (TCL) Enables interrupt signaling from CQTCL register.
  [2] CQREDSI — CQREDSI - Response Error Detected Signal Enable (TCC) Enables interrupt signaling from CQREDI register.
  [1] CQTCCSI — CQTCCSI - Task Complete Signal Enable (TCC) Enables interrupt signaling from CQTCC register.
  [0] CQHACSI — CQHACSI - Halt Complete Signal Enable (HAC) Enables interrupt signaling from CQHLT register.
0x41C CQRS07 — CQRS07 - Interrupt Coalescing This register allows to group a CQ transfer and report single interrupt for entire group of requested tasks.
  [31] CQICED — CQICED - Interrupt Coalescing Enable/Disable Enables coalescing mechanism allowing to generate coalescing interrupts.
  [20] CQICSB ro — CQICSB - Interrupt Coalescing Status Bit (ICSB) CQE sets this bit 1 when any task with INT=0 is completed.
  [16] CQICCTR — CQICCTR - Counter and Timer Reset(ICCTR) S/W resets interrupt coalescing timer and counter.
  [15] CQICCTHWEN — CQICCTHWEN - Interrupt Coalescing Counter Threshold Write Enable (ICCTHWEN) This is write enable for CQICCTH. When this bit is set 1, the field will be updated.
  [12:8] CQICCTH — CQICCTH - Interrupt Coalescing Counter Threshold (ICCTH) CQE increments internal counter when task with INT=0 is completed. When internal counter reaches this value the coalescing generates interrupt. S/W can select treshold value in range 1 to 31. S/W can disable internal counter and interrupt generation by setting this field to 0.
  [7] CQICTOVALEN — CQICTOVALEN - Interrupt Coalescing Timeout Value Write Enable (ICTOVALWEN) This is write enable for CQICTOVAL. When this bit is set 1, the field will be updated.
  [6:0] CQICTOVAL — CQICTOVAL - Interrupt Coalescing Timeout Value (ICTOVAL) CQE generates interrupt when internal counter reaches period defined in this field. The counter starts when first transfer with INT=0 is completed. The counter increments each time when Internal Clock * 1024 period elapsed. S/W can disable this timer by setting this filed to 0.
0x420 CQRS08 — CQRS08 - Command Queuing Task Descriptor List Base Address
  [31:0] CQTDLBA — CQTDLBA - Task Descriptor List Base Address (lower) Base address (32 lower bits) of the Task Descriptor List. S/W will write values aligned to 1kB boundary (lower 10 bits have to be 0). The hardware ignores 10 lower bits. S/W will update this register only when CQE is disabled.
0x424 CQRS09 — CQRS09 - Command Queuing Task Descriptor List Base Address Upper 32 Bits
  [31:0] CQTDLBAU — CQTDLBAU - Task Descriptor List Base Address (upper) Base address (32 upper bits) of the Task descriptor List. This register is not used in 32 bit addressing mode (S/W does not change this value). S/W will update this register only when CQE is disabled.
0x428 CQRS10 — CQRS10 - Command Queuing Task Doorbell CQ has 32 tasks have individual bits to start operation on desired task. The S/W writes 1 on any position from 0 to 31 to start task 0 to 31. The S/W can request more than one task in single write. The CQ Engine process tasks in order they were requested: - when more than one task is requested in single register write, the task with lower number has higher priority over task with higher number - task(s) requested in earlier register write has higher priority over task(s) in later register write The order of the tasks are maintained during all phases of transaction. If given task is not ready for execution, the CQ Engine takes next task with highest number. CQ Engine needs several clock cycles to push requested in the single register write Task Doorbell to queue. The slave interface ends write transfer as soon all tasks are in the queue. When S/W writes 0 to bit in this register, the related task won't start - this value is ignored. Task Doorbell bit remain 1 until task execution is completed, task is cleared by Clear All Task or Clear Task with this number or CQ Engine is disabled (CQE=0).
  [n] CQTD{n:02} (n=0..31) — CQTD{n:02} - Command Queuing Task Doorbell #{n:02}
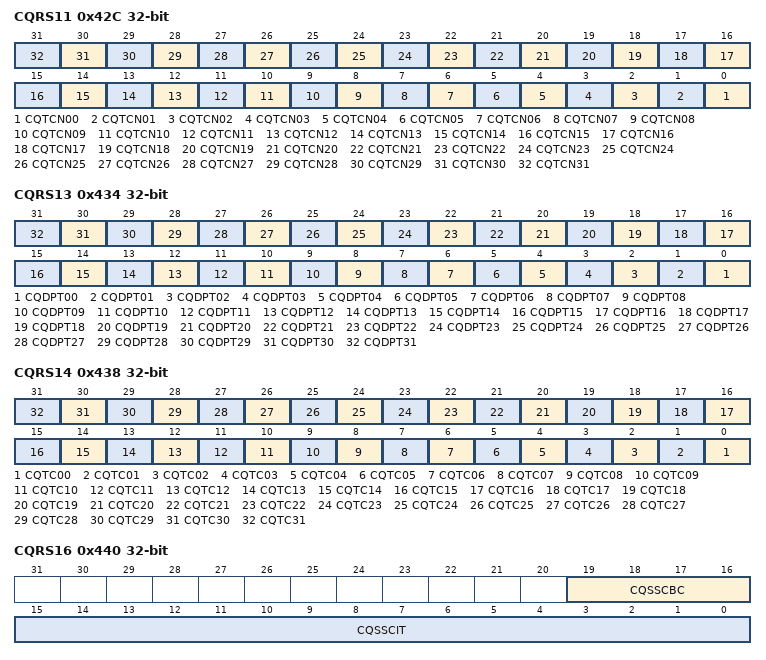
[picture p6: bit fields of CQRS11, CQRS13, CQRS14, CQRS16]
0x42C CQRS11 — CQRS11 - Task Complete Notification 32 bits related to 32 tasks. If task N is completed N bit is set 1. Bit that is set 1 can be cleared by writing 1 to this bit.
  [n] CQTCN{n:02} (n=0..31) — CQTCN{n:02} - Task Completion Notification #{n:02}
0x430 CQRS12 ro — CQRS12 - Device Queue Status
  [31:0] CQDQS — CQDQS - Device Queue Status This register reflects to eMMC device status. Task N is ready for execution when bit N in this register is set to 1. This register is updated each time response for SEND_QUEUE_STATUS (CMD13) is received.
0x434 CQRS13 ro — CQRS13 - Device Pending Tasks This register information which task is submitted to eMMC (CMD44 and CMD45 was sent) and is not executed. Task N is submitted and not executed when N bit is set 1. Bit N is cleared when task N is completed.
  [n] CQDPT{n:02} (n=0..31) — CQDPT{n:02} - Device Pending Tasks #{n:02}
0x438 CQRS14 — CQRS14 - Task Clear S/W writes 1 to N bit of this register to clear task N. Bit remains 1 until clear operation is completed. Once operations ends, the CQE clears this bit to 0. The S/W has to ensure the CQ Engine is halted before clearing tasks. The S/W can clear only single task. When any bit of this register is set, the S/W has no to request new task clear. This operation clears only task in the Host Controller. The S/W should take care about clearing task in the device. Writing 0 to register is ignored.
  [n] CQTC{n:02} (n=0..31) — CQTC{n:02} - Command Queuing Task Clear #{n:02}
0x440 CQRS16 — CQRS16 - Send Status Configuration 1
  [19:16] CQSSCBC — CQSSCBC - Send Status Command Block Counter (CBC) S/W can define if and when CQE sends SEND_QUEUE_STATUS (CMD13) command during data transfer. When this register is set 0, the CQE does not send CMD13 during data transfer. The value is 1, 2, or N means, the CQE sends CMD13 is transferred during last, one before last, or (N-1) before last block, respectively. Accepted register value range is 0 to 15.
  [15:0] CQSSCIT — CQSSCIT - Send Status Command Idle Timer (CIT) When CQE is in idle, the host controller can poll device by sending SEND_QUEUE_STATUS (CMD13) with interval defined by this register. Accepted register value is in range 1 to 65535. The interval can be calculated as CQSSICT * internal clock period.
0x444 CQRS17 — CQRS17 - Send Status Configuration 2
  [15:0] CQSQSR — CQSQSR - Send Queue Status RCA S/W writes 16-bit RCA value which is send as an argument in SEND_QUEUE_STATUS (CMD13) command.
0x448 CQRS18 ro — CQRS18 - Command Response for Direct-Command Task
  [31:0] CQDCLR — CQDCLR - Direct Command Last Response CQE holds the last DCMD command response.
0x450 CQRS20 — CQRS20 - Response Mode Error Mask
  [31:0] CQRMEM — CQRMEM - Response Mode Error Mask CQE is able to automatically detect errors in response. The S/W defines which bits of the response need to be checked. All bits set to 1 (written by S/W) are analyzed. The CQE reports Response Error Detected Interrupt (CQREDI) when N bit of CQRMEM is 1 and N bit of response is 1. Response for SEND_QUEUE_STATUS (CMD13) automatically sent by CQE is ignored.
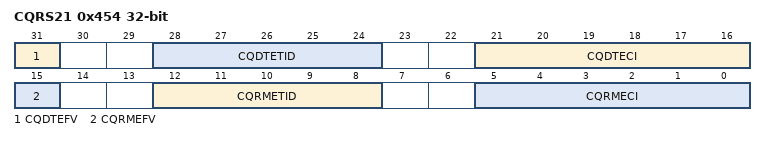
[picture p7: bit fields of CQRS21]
0x454 CQRS21 ro — CQRS21 - Task Error Information
  [31] CQDTEFV — CQDTEFV - Data Transfer Error Fields Valid Host sets this bit to 1 when error is detected during data transfer. Host clears this bit to 0 when error is detected and there is no active data transfer.
  [28:24] CQDTETID — CQDTETID - Data Transfer Error Task ID Host updates this field with ID of the task with active data transfer when error occurred during the data transfer.
  [21:16] CQDTECI — CQDTECI - Data Transfer Error Command Index Host updates this field with index of the data transfer command executed when error occurred during the data transfer.
  [15] CQRMEFV — CQRMEFV - Response Mode Error Fields Valid Host sets this bit to 1 when error is detected and command transaction is active. Host sets this bit to 0 when error is detected and command transaction is no active.
  [12:8] CQRMETID — CQRMETID - Response Mode Error Task ID Host updates this field with ID of the task with active command transfer when error occurred during the command transaction.
  [5:0] CQRMECI — CQRMECI - Response Mode Error Command Index Host updates this field with index of the command executed when error occurred during the command transaction.
0x458 CQRS22 ro — CQRS22 - Command Response Index
  [5:0] CQLCRI — CQLCRI - Last Command Response Index Host updates this field with command index when response is received.
0x45C CQRS23 ro — CQRS23 - Command Response Argument
  [31:0] CQLCRA — CQLCRA - Last Command Response Argument Host updates this field with command argument when response is received.
